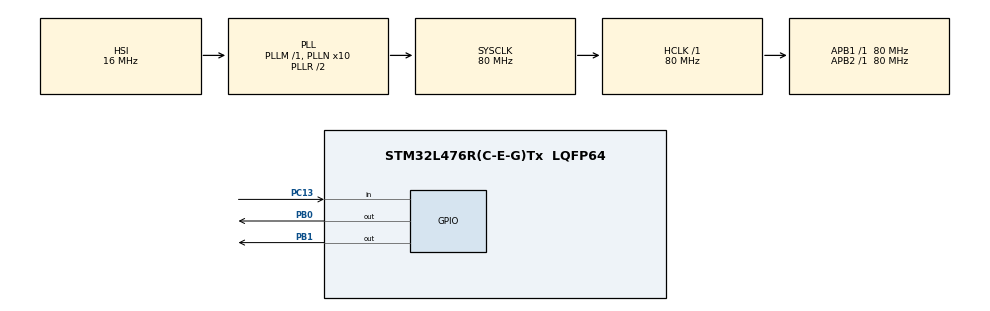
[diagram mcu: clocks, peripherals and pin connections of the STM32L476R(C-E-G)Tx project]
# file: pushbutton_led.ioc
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Mcu.Family=STM32L4
Mcu.Name=STM32L476R(C-E-G)Tx
Mcu.Package=LQFP64
NVIC.PriorityGroup=NVIC_PRIORITYGROUP_4
PB0.Signal=GPIO_Output
PB1.Signal=GPIO_Output
PC13.Signal=GPIO_Input
PH0-OSC_IN\ (PH0).Mode=HSE-External-Oscillator
PH0-OSC_IN\ (PH0).Signal=RCC_OSC_IN
PH1-OSC_OUT\ (PH1).Mode=HSE-External-Oscillator
PH1-OSC_OUT\ (PH1).Signal=RCC_OSC_OUT
ProjectManager.HeapSize=0x200
ProjectManager.StackSize=0x400
ProjectManager.TargetToolchain=STM32CubeIDE
RCC.ADCFreq_Value=64000000
RCC.AHBFreq_Value=80000000
RCC.APB1Freq_Value=80000000
RCC.APB1TimFreq_Value=80000000
RCC.APB2Freq_Value=80000000
RCC.APB2TimFreq_Value=80000000
RCC.CortexFreq_Value=80000000
RCC.HCLKFreq_Value=80000000
RCC.HSE_VALUE=8000000
RCC.HSI_VALUE=16000000
RCC.MSI_VALUE=4000000
RCC.PLLN=10
RCC.PLLSourceVirtual=RCC_PLLSOURCE_HSI
RCC.PREFETCH_ENABLE=1
RCC.SYSCLKFreq_VALUE=80000000
RCC.SYSCLKSource=RCC_SYSCLKSOURCE_PLLCLK
RCC.USBFreq_Value=64000000
RCC.VCOOutputFreq_Value=160000000
board=NUCLEO-L476RG

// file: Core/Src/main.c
/* USER CODE BEGIN Header */
/**
  ******************************************************************************
  * @file           : main.c
  * @brief          : Main program body
  ******************************************************************************
  * @attention
  *
  * Copyright (c) 2026 STMicroelectronics.
  * All rights reserved.
  *
  * This software is licensed under terms that can be found in the LICENSE file
  * in the root directory of this software component.
  * If no LICENSE file comes with this software, it is provided AS-IS.
  *
  ******************************************************************************
  */
/* USER CODE END Header */
#include "main.h"

void SystemClock_Config(void);
static void MX_GPIO_Init(void);

int main(void)
{

  /* MCU Configuration--------------------------------------------------------*/

  /* Reset of all peripherals, Initializes the Flash interface and the Systick. */
  HAL_Init();

  /* Configure the system clock */
  SystemClock_Config();

  /* Initialize all configured peripherals */
  MX_GPIO_Init();

  /* Infinite loop */
  while (1)
  {

    /* USER CODE BEGIN 3 */
	  // Check if the Blue Button (PC13) is being pressed (reads RESET when pressed)
	        if (HAL_GPIO_ReadPin(GPIOC, GPIO_PIN_13) == GPIO_PIN_RESET)
	        {
	            // --- BUTTON IS PRESSED ---
	            HAL_GPIO_WritePin(GPIOB, GPIO_PIN_0, GPIO_PIN_SET);   // Turn LED 1 ON solid
	            HAL_GPIO_WritePin(GPIOB, GPIO_PIN_1, GPIO_PIN_RESET); // Turn LED 2 OFF solid
	        }
	        else
	        {
	            // --- BUTTON IS NOT PRESSED ---
	            HAL_GPIO_WritePin(GPIOB, GPIO_PIN_0, GPIO_PIN_RESET); // Turn LED 1 OFF solid
	            HAL_GPIO_WritePin(GPIOB, GPIO_PIN_1, GPIO_PIN_SET);   // Turn LED 2 ON solid
	        }
  }
  /* USER CODE END 3 */
}

void SystemClock_Config(void)
{
  RCC_OscInitTypeDef RCC_OscInitStruct = {0};
  RCC_ClkInitTypeDef RCC_ClkInitStruct = {0};

  /** Configure the main internal regulator output voltage
  */
  if (HAL_PWREx_ControlVoltageScaling(PWR_REGULATOR_VOLTAGE_SCALE1) != HAL_OK)
  {
    Error_Handler();
  }

  /** Initializes the RCC Oscillators according to the specified parameters
  * in the RCC_OscInitTypeDef structure.
  */
  RCC_OscInitStruct.OscillatorType = RCC_OSCILLATORTYPE_HSI;
  RCC_OscInitStruct.HSIState = RCC_HSI_ON;
  RCC_OscInitStruct.HSICalibrationValue = RCC_HSICALIBRATION_DEFAULT;
  RCC_OscInitStruct.PLL.PLLState = RCC_PLL_ON;
  RCC_OscInitStruct.PLL.PLLSource = RCC_PLLSOURCE_HSI;
  RCC_OscInitStruct.PLL.PLLM = 1;
  RCC_OscInitStruct.PLL.PLLN = 10;
  RCC_OscInitStruct.PLL.PLLP = RCC_PLLP_DIV7;
  RCC_OscInitStruct.PLL.PLLQ = RCC_PLLQ_DIV2;
  RCC_OscInitStruct.PLL.PLLR = RCC_PLLR_DIV2;
  if (HAL_RCC_OscConfig(&RCC_OscInitStruct) != HAL_OK)
  {
    Error_Handler();
  }

  /** Initializes the CPU, AHB and APB buses clocks
  */
  RCC_ClkInitStruct.ClockType = RCC_CLOCKTYPE_HCLK|RCC_CLOCKTYPE_SYSCLK
                              |RCC_CLOCKTYPE_PCLK1|RCC_CLOCKTYPE_PCLK2;
  RCC_ClkInitStruct.SYSCLKSource = RCC_SYSCLKSOURCE_PLLCLK;
  RCC_ClkInitStruct.AHBCLKDivider = RCC_SYSCLK_DIV1;
  RCC_ClkInitStruct.APB1CLKDivider = RCC_HCLK_DIV1;
  RCC_ClkInitStruct.APB2CLKDivider = RCC_HCLK_DIV1;

  if (HAL_RCC_ClockConfig(&RCC_ClkInitStruct, FLASH_LATENCY_4) != HAL_OK)
  {
    Error_Handler();
  }
}

static void MX_GPIO_Init(void)
{
  GPIO_InitTypeDef GPIO_InitStruct = {0};

  /* GPIO Ports Clock Enable */
  __HAL_RCC_GPIOC_CLK_ENABLE();
  __HAL_RCC_GPIOH_CLK_ENABLE();
  __HAL_RCC_GPIOB_CLK_ENABLE();

  /*Configure GPIO pin Output Level */
  HAL_GPIO_WritePin(GPIOB, GPIO_PIN_0|GPIO_PIN_1, GPIO_PIN_RESET);

  /*Configure GPIO pin : PC13 */
  GPIO_InitStruct.Pin = GPIO_PIN_13;
  GPIO_InitStruct.Mode = GPIO_MODE_INPUT;
  GPIO_InitStruct.Pull = GPIO_NOPULL;
  HAL_GPIO_Init(GPIOC, &GPIO_InitStruct);

  /*Configure GPIO pins : PB0 PB1 */
  GPIO_InitStruct.Pin = GPIO_PIN_0|GPIO_PIN_1;
  GPIO_InitStruct.Mode = GPIO_MODE_OUTPUT_PP;
  GPIO_InitStruct.Pull = GPIO_NOPULL;
  GPIO_InitStruct.Speed = GPIO_SPEED_FREQ_LOW;
  HAL_GPIO_Init(GPIOB, &GPIO_InitStruct);

}

void Error_Handler(void)
{
  __disable_irq();
  while (1)
  {
  }
}
